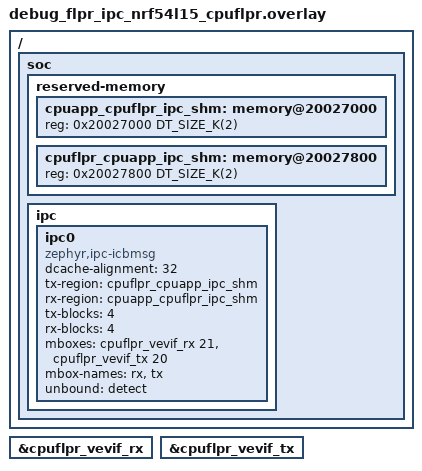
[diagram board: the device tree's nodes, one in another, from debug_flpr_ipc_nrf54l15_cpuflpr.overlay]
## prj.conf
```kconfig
CONFIG_XIP=y

CONFIG_GNU_C_EXTENSIONS=y
CONFIG_DEBUG_OPTIMIZATIONS=y

CONFIG_ASSERT=y

CONFIG_LOG=y
CONFIG_LOG_OUTPUT=y


CONFIG_MBOX=y
CONFIG_IPC_SERVICE=y
CONFIG_IPC_SERVICE_ICMSG=y
```

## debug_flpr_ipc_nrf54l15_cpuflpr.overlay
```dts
/ {
	soc {
		reserved-memory {
			#address-cells = <1>;
			#size-cells = <1>;

			/* Keep these addresses and sizes identical to the CPUAPP overlay. */
			cpuapp_cpuflpr_ipc_shm: memory@20027000 {
				reg = <0x20027000 DT_SIZE_K(2)>;
			};

			cpuflpr_cpuapp_ipc_shm: memory@20027800 {
				reg = <0x20027800 DT_SIZE_K(2)>;
			};
		};

		ipc {
			ipc0: ipc0 {
				compatible = "zephyr,ipc-icbmsg";
				dcache-alignment = <32>;
				/* Reverse CPUAPP's directions so each TX region is the peer's RX. */
				tx-region = <&cpuflpr_cpuapp_ipc_shm>;
				rx-region = <&cpuapp_cpuflpr_ipc_shm>;
				tx-blocks = <4>;
				rx-blocks = <4>;
				mboxes = <&cpuflpr_vevif_rx 21>, <&cpuflpr_vevif_tx 20>;
				mbox-names = "rx", "tx";
				unbound = "detect";
				status = "okay";
			};
		};
	};
};

&cpuflpr_vevif_rx {
	status = "okay";
};

&cpuflpr_vevif_tx {
	status = "okay";
};
```

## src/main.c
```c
#include <stdio.h>
#include <zephyr/kernel.h>

#include "ipc.h"
#include "ipc_logger.h"

#include <zephyr/logging/log.h>

LOG_MODULE_REGISTER(Main, LOG_LEVEL_INF);

int main(void)
{
    ipc_logger_init();
    /* Wait for CPUAPP before emitting the application's first periodic log. */
    while (!ipc_get_dbgmsg_bounded())
    {
        k_sleep(K_MSEC(10));
    }
    while (1)
    {
        LOG_INF("Hello world from flpr");
        k_sleep(K_MSEC(1000));
    }
    return 0;
}
```

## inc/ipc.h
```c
#ifndef __ipc_h
#define __ipc_h

#include <stdio.h>
#include <stdbool.h>
#include <stdint.h>

/* Register FLPR's log endpoint; the bound callback signals readiness later. */
void dbgmsg_ipc_init(void);
/* Return the current bound flag (0 or 1) without consuming it. */
uint32_t ipc_get_dbgmsg_bounded(void);
/* Send a text chunk if bound; unbound chunks and send errors are not retried. */
void dbgmsg_ipc_send(const void *data, size_t len);
void magdata_ipc_init(void);
int magdata_ipc_send(const void *data, size_t len);
#endif
```

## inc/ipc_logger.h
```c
#include <stdio.h>
#include <stdbool.h>
#include <stdint.h>

/* Set up IPC and enable the backend that forwards FLPR's formatted logs. */
void ipc_logger_init(void);
```

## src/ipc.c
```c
#include "ipc.h"

#include <zephyr/kernel.h>
#include <zephyr/device.h>

#include <zephyr/ipc/ipc_service.h>

#include <zephyr/logging/log.h>

LOG_MODULE_REGISTER(flpr_ipc, CONFIG_LOG_DEFAULT_LEVEL);

// Debug message IPC

/* Use the semaphore count as a connection flag: 0 = unbound, 1 = bound. */
K_SEM_DEFINE(dbgmsg_bound_sem, 0, 1);

static void dbgmsg_bound(void *priv)
{
    k_sem_give(&dbgmsg_bound_sem);
    LOG_INF("dbgmsg ep bounded");
}
static void dbgmsg_unbound(void *priv)
{
    /* Consume the bound token so subsequent log chunks are no longer sent. */
    k_sem_take(&dbgmsg_bound_sem, K_FOREVER);
    LOG_INF("dbgmsg ep unbounded");
}
static void ep_error(const char *err, void *priv)
{
    LOG_ERR("ep error %s", err);
}
uint32_t ipc_get_dbgmsg_bounded(void)
{
    /* Inspect the flag without consuming the token used by the send guard. */
    return k_sem_count_get(&dbgmsg_bound_sem);
}

static struct ipc_ept_cfg dbgmsg_ep_cfg = {
    .cb = {
        .bound = dbgmsg_bound,
        .unbound = dbgmsg_unbound,
        //.received = dbgmsg_recv,
        .error = ep_error,
    },
    /* This name must match the endpoint registered by CPUAPP. */
    .name = "dbgmsg_ep",
};

static struct ipc_ept dbgmsg_ep;
static const struct device *dbgmsg_ipc_dev;

void dbgmsg_ipc_init(void)
{

    dbgmsg_ipc_dev = DEVICE_DT_GET(DT_NODELABEL(ipc0));
    int ret;

    ret = ipc_service_open_instance(dbgmsg_ipc_dev);
    /* An already-open IPC instance can still be used to register this endpoint. */
    if ((ret < 0) && (ret != -EALREADY))
    {
        LOG_ERR("ipc_service_open_instance() failure");
    }
    ret = ipc_service_register_endpoint(dbgmsg_ipc_dev, &dbgmsg_ep, &dbgmsg_ep_cfg);
    if (ret < 0)
    {
        LOG_ERR("ipc_service_register_endpoint() failure");
    }
}

void dbgmsg_ipc_send(const void *data, size_t len)
{
    /* Discard chunks while unbound; this wrapper does not queue or retry logs. */
    if (k_sem_count_get(&dbgmsg_bound_sem) > 0)
    {
        ipc_service_send(&dbgmsg_ep, data, len);
    }
}
```

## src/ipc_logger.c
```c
#include "ipc_logger.h"

#include <zephyr/logging/log_backend.h>
#include <zephyr/logging/log_output.h>
#include <zephyr/logging/log_ctrl.h>

#include "ipc.h"

/* Formatting scratch space; longer log messages can be flushed in chunks. */
static uint8_t log_format_buffer[256];

static int dbgmsg_ipc_out_func(uint8_t *data, size_t length, void *ctx)
{
    dbgmsg_ipc_send(data, length);
    /* Mark the chunk consumed even if IPC discarded it or failed to send it. */
    return length;
}

LOG_OUTPUT_DEFINE(dbgmsg_ipc_log_output, dbgmsg_ipc_out_func, log_format_buffer, sizeof(log_format_buffer));

static void logger_process(const struct log_backend *const backend, union log_msg_generic *msg)
{
    /* Forward readable text with a severity prefix and formatted timestamp. */
    uint32_t flags = LOG_OUTPUT_FLAG_LEVEL | LOG_OUTPUT_FLAG_TIMESTAMP | LOG_OUTPUT_FLAG_FORMAT_TIMESTAMP;
    log_output_msg_process(&dbgmsg_ipc_log_output, &msg->log, flags);
}

static const struct log_backend_api dbgmsg_log_backend_api = {
    .process = logger_process,
};
/* Disable autostart so main() can set up IPC before enabling this backend. */
LOG_BACKEND_DEFINE(dbgmsg_ipc_backend, dbgmsg_log_backend_api, false);

void ipc_logger_init(void)
{
    dbgmsg_ipc_init();
    /* Binding is asynchronous; main() waits before producing application logs. */
    log_backend_enable(&dbgmsg_ipc_backend, NULL, CONFIG_LOG_MAX_LEVEL);
}
```
